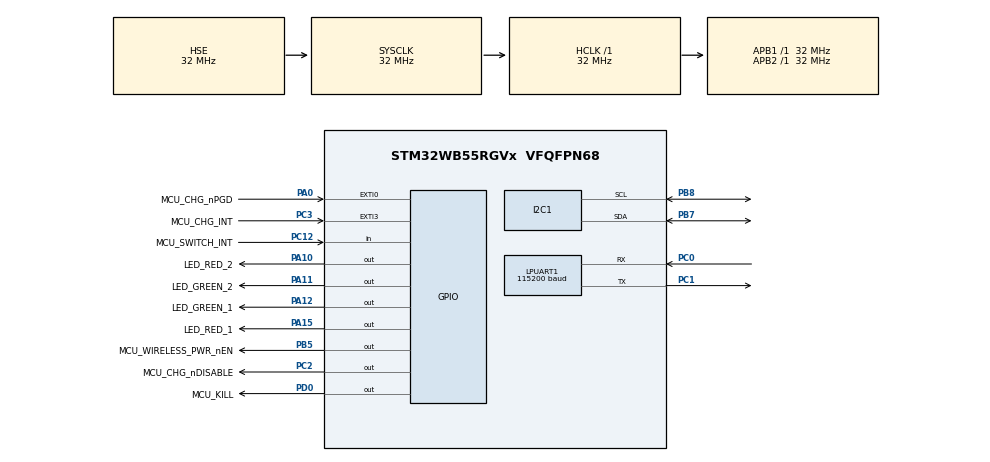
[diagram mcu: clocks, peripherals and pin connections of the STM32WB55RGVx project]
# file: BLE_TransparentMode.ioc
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Dma.LPUART1_TX.0.Direction=DMA_MEMORY_TO_PERIPH
Dma.LPUART1_TX.0.EventEnable=DISABLE
Dma.LPUART1_TX.0.Instance=DMA1_Channel2
Dma.LPUART1_TX.0.MemDataAlignment=DMA_MDATAALIGN_BYTE
Dma.LPUART1_TX.0.MemInc=DMA_MINC_ENABLE
Dma.LPUART1_TX.0.Mode=DMA_NORMAL
Dma.LPUART1_TX.0.PeriphDataAlignment=DMA_PDATAALIGN_BYTE
Dma.LPUART1_TX.0.PeriphInc=DMA_PINC_DISABLE
Dma.LPUART1_TX.0.Polarity=HAL_DMAMUX_REQ_GEN_RISING
Dma.LPUART1_TX.0.Priority=DMA_PRIORITY_LOW
Dma.LPUART1_TX.0.RequestNumber=1
Dma.LPUART1_TX.0.SignalID=NONE
Dma.LPUART1_TX.0.SyncEnable=DISABLE
Dma.LPUART1_TX.0.SyncPolarity=HAL_DMAMUX_SYNC_NO_EVENT
Dma.LPUART1_TX.0.SyncRequestNumber=1
Dma.LPUART1_TX.0.SyncSignalID=NONE
Dma.Request0=LPUART1_TX
I2C1.Timing=0x00B07CB4
LPUART1.BaudRate=115200
Mcu.Family=STM32WB
Mcu.Name=STM32WB55RGVx
Mcu.Package=VFQFPN68
NVIC.DMA1_Channel2_IRQn=true\:0\:0\:false\:false\:true\:false\:true\:true
NVIC.HSEM_IRQn=true\:0\:0\:false\:false\:true\:false\:true\:true
NVIC.IPCC_C1_RX_IRQn=true\:0\:0\:false\:false\:true\:true\:true\:true
NVIC.IPCC_C1_TX_IRQn=true\:0\:0\:false\:false\:true\:true\:true\:true
NVIC.LPUART1_IRQn=true\:0\:0\:false\:false\:true\:true\:true\:true
NVIC.PriorityGroup=NVIC_PRIORITYGROUP_4
NVIC.RTC_WKUP_IRQn=true\:0\:0\:false\:false\:true\:true\:true\:true
NVIC.TIM1_TRG_COM_TIM17_IRQn=true\:0\:0\:false\:false\:true\:true\:true\:true
OSC_IN.Mode=HSE-External-Oscillator
OSC_IN.Signal=RCC_OSC_IN
OSC_OUT.Mode=HSE-External-Oscillator
OSC_OUT.Signal=RCC_OSC_OUT
PA0.GPIO_Label=MCU_CHG_nPGD
PA0.Signal=GPXTI0
PA10.GPIO_Label=LED_RED_2
PA10.PinState=GPIO_PIN_SET
PA10.Signal=GPIO_Output
PA11.GPIO_Label=LED_GREEN_2
PA11.PinState=GPIO_PIN_SET
PA11.Signal=GPIO_Output
PA12.GPIO_Label=LED_GREEN_1
PA12.PinState=GPIO_PIN_SET
PA12.Signal=GPIO_Output
PA15.GPIO_Label=LED_RED_1
PA15.PinState=GPIO_PIN_SET
PA15.Signal=GPIO_Output
PB5.GPIO_Label=MCU_WIRELESS_PWR_nEN
PB5.Signal=GPIO_Output
PB7.Mode=I2C
PB7.Signal=I2C1_SDA
PB8.Mode=I2C
PB8.Signal=I2C1_SCL
PC0.Mode=Asynchronous
PC0.Signal=LPUART1_RX
PC1.Mode=Asynchronous
PC1.Signal=LPUART1_TX
PC12.GPIO_Label=MCU_SWITCH_INT
PC12.Signal=GPIO_Input
PC14-OSC32_IN.Mode=LSE-External-Oscillator
PC14-OSC32_IN.Signal=RCC_OSC32_IN
PC15-OSC32_OUT.Mode=LSE-External-Oscillator
PC15-OSC32_OUT.Signal=RCC_OSC32_OUT
PC2.GPIO_Label=MCU_CHG_nDISABLE
PC2.PinState=GPIO_PIN_SET
PC2.Signal=GPIO_Output
PC3.GPIO_Label=MCU_CHG_INT
PC3.Signal=GPXTI3
PD0.GPIO_Label=MCU_KILL
PD0.Signal=GPIO_Output
ProjectManager.HeapSize=0x400
ProjectManager.StackSize=0x1000
ProjectManager.TargetToolchain=EWARM V8
RCC.ADCFreq_Value=64000000
RCC.AHBFreq_Value=32000000
RCC.APB1Freq_Value=32000000
RCC.APB1TimFreq_Value=32000000
RCC.APB2Freq_Value=32000000
RCC.APB2TimFreq_Value=32000000
RCC.APB3Freq_Value=16000000
RCC.CortexFreq_Value=32000000
RCC.HCLKFreq_Value=32000000
RCC.HSE_VALUE=32000000
RCC.HSI48_VALUE=48000000
RCC.HSI_VALUE=16000000
RCC.LSE_Drive_Capability=RCC_LSEDRIVE_LOW
RCC.PLLSourceVirtual=RCC_PLLSOURCE_HSI
RCC.RFWKPClockSelection=RCC_RFWKPCLKSOURCE_LSE
RCC.RTCClockSelection=RCC_RTCCLKSOURCE_LSE
RCC.SMPSCLockSelection=RCC_SMPSCLKSOURCE_HSE
RCC.SMPSCLockSelectionVirtual=RCC_SMPSCLKSOURCE_HSE
RCC.SMPSDivider=4
RCC.SYSCLKFreq_VALUE=32000000
RCC.SYSCLKSource=RCC_SYSCLKSOURCE_HSE
RCC.USBFreq_Value=64000000
RCC.VCOOutputFreq_Value=128000000
RF1.Mode=RF1_Activate
RF1.Signal=RF_RF1
STM32_WPAN.BLE_APPLICATION_TYPE=TRANSPARENT_MODE
STM32_WPAN.CFG_BLE_LSE_SOURCE=0
STM32_WPAN.CFG_BLE_MAX_ADV_DATA_LEN=207
STM32_WPAN.CFG_BLE_MAX_ADV_SET_NBR=8
STM32_WPAN.CFG_BLE_MAX_CONN_EVENT_LENGTH=0xFFFFFFFF
STM32_WPAN.CFG_BLE_MAX_TX_POWER=6
STM32_WPAN.CFG_BLE_MIN_TX_POWER=-40
STM32_WPAN.CFG_BLE_NUM_LINK=8
STM32_WPAN.CFG_BLE_OPTIONS_CS_ALGO=SHCI_C2_BLE_INIT_OPTIONS_CS_ALGO2
STM32_WPAN.CFG_BLE_OPTIONS_EXT_ADV=SHCI_C2_BLE_INIT_OPTIONS_EXT_ADV
STM32_WPAN.CFG_DEBUGGER_SUPPORTED=1
STM32_WPAN.CFG_HW_LPUART1_ENABLED=1
STM32_WPAN.CFG_HW_USART1_ENABLED=1
STM32_WPAN.CFG_LPM_SUPPORTED=0
STM32_WPAN.CFG_RTCCLK_DIV=16
STM32_WPAN.CFG_RTCCLK_DIVIDER_CONF=0
STM32_WPAN.CFG_RTC_ASYNCH_PRESCALER=0x0F
STM32_WPAN.CFG_UART_GUI=hw_lpuart1
STM32_WPAN.CFG_USE_SMPS=0
TIM17.AutoReloadPreload=TIM_AUTORELOAD_PRELOAD_ENABLE
TIM17.Period=500
TIM17.Prescaler=31999
VP_HSEM_VS_HSEM.Mode=HSEM_Activate
VP_IPCC_VS_IPCC.Mode=IPCC_Activate
VP_MEMORYMAP_VS_MEMORYMAP.Mode=CurAppReg
VP_RTC_VS_RTC_Activate.Mode=RTC_Enabled
VP_RTC_VS_RTC_WakeUp_intern.Mode=WakeUp
VP_SEQUENCER_VS_SEQUENCER.Mode=SEQUENCER_Enabled
VP_STM32_WPAN_VS_BLE_HOST.Mode=STM32_WPAN_Enabled
VP_TIM17_VS_ClockSourceINT.Mode=Enable_Timer
VP_TINY_LPM_VS_TINY_LPM.Mode=TINY_LPM_Enabled
board=custom

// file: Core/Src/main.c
/* USER CODE BEGIN Header */
/**
  ******************************************************************************
 * @file    main.c
 * @author  MCD Application Team
 * @brief   BLE application with BLE core
 *
  ******************************************************************************
  * @attention
  *
  * Copyright (c) 2019-2021 STMicroelectronics.
  * All rights reserved.
  *
  * This software is licensed under terms that can be found in the LICENSE file
  * in the root directory of this software component.
  * If no LICENSE file comes with this software, it is provided AS-IS.
  *
  ******************************************************************************
  @verbatim
  ==============================================================================
                    ##### IMPORTANT NOTE #####
  ==============================================================================

  This application requests having the stm32wb5x_BLE_Stack_fw.bin binary
  flashed on the Wireless Coprocessor.
  If it is not the case, you need to use STM32CubeProgrammer to load the appropriate
  binary.

  All available binaries are located under following directory:
  /Projects/STM32_Copro_Wireless_Binaries

  Refer to UM2237 to learn how to use/install STM32CubeProgrammer.
  Refer to /Projects/STM32_Copro_Wireless_Binaries/ReleaseNote.html for the
  detailed procedure to change the Wireless Coprocessor binary.

  @endverbatim
  ******************************************************************************
  */
/* USER CODE END Header */
#include "main.h"

/* USER CODE BEGIN Includes */
#include "led.h"
#include "charger_control.h"

/* USER CODE END Includes */

I2C_HandleTypeDef hi2c1;

IPCC_HandleTypeDef hipcc;

UART_HandleTypeDef hlpuart1;
DMA_HandleTypeDef hdma_lpuart1_tx;

RTC_HandleTypeDef hrtc;

TIM_HandleTypeDef htim17;

void SystemClock_Config(void);
void PeriphCommonClock_Config(void);
static void MX_RF_Init(void);
static void MX_GPIO_Init(void);
static void MX_DMA_Init(void);
static void MX_RTC_Init(void);
static void MX_IPCC_Init(void);
void MX_LPUART1_UART_Init(void);
static void MX_I2C1_Init(void);
static void MX_TIM17_Init(void);

int main(void)
{

  /* MCU Configuration--------------------------------------------------------*/

  /* Reset of all peripherals, Initializes the Flash interface and the Systick. */
  HAL_Init();
  /* Config code for STM32_WPAN (HSE Tuning must be done before system clock configuration) */
  MX_APPE_Config();

  /* Configure the system clock */
  SystemClock_Config();

  /* Configure the peripherals common clocks */
  PeriphCommonClock_Config();

  /* IPCC initialisation */
  MX_IPCC_Init();

  /* Initialize all configured peripherals */
  MX_RF_Init();
  MX_GPIO_Init();
  MX_DMA_Init();
  MX_RTC_Init();
  MX_LPUART1_UART_Init();
  MX_I2C1_Init();
  MX_TIM17_Init();
  /* USER CODE BEGIN 2 */

  LED_Init();
  CHGC_Init();

  // only start the timer after LED & CHRG are initialised
  HAL_TIM_Base_Start_IT(&htim17);

  /* USER CODE END 2 */

  /* Init code for STM32_WPAN */
  MX_APPE_Init();

  /* Infinite loop */
	while(1)
	{
    MX_APPE_Process();

  }
}

void SystemClock_Config(void)
{
  RCC_OscInitTypeDef RCC_OscInitStruct = {0};
  RCC_ClkInitTypeDef RCC_ClkInitStruct = {0};

  /** Configure LSE Drive Capability
  */
  HAL_PWR_EnableBkUpAccess();
  __HAL_RCC_LSEDRIVE_CONFIG(RCC_LSEDRIVE_LOW);

  /** Configure the main internal regulator output voltage
  */
  __HAL_PWR_VOLTAGESCALING_CONFIG(PWR_REGULATOR_VOLTAGE_SCALE1);

  /** Initializes the RCC Oscillators according to the specified parameters
  * in the RCC_OscInitTypeDef structure.
  */
  RCC_OscInitStruct.OscillatorType = RCC_OSCILLATORTYPE_HSI|RCC_OSCILLATORTYPE_HSE
                              |RCC_OSCILLATORTYPE_LSE;
  RCC_OscInitStruct.HSEState = RCC_HSE_ON;
  RCC_OscInitStruct.LSEState = RCC_LSE_ON;
  RCC_OscInitStruct.HSIState = RCC_HSI_ON;
  RCC_OscInitStruct.HSICalibrationValue = RCC_HSICALIBRATION_DEFAULT;
  RCC_OscInitStruct.PLL.PLLState = RCC_PLL_NONE;
  if (HAL_RCC_OscConfig(&RCC_OscInitStruct) != HAL_OK)
  {
    Error_Handler();
  }

  /** Configure the SYSCLKSource, HCLK, PCLK1 and PCLK2 clocks dividers
  */
  RCC_ClkInitStruct.ClockType = RCC_CLOCKTYPE_HCLK4|RCC_CLOCKTYPE_HCLK2
                              |RCC_CLOCKTYPE_HCLK|RCC_CLOCKTYPE_SYSCLK
                              |RCC_CLOCKTYPE_PCLK1|RCC_CLOCKTYPE_PCLK2;
  RCC_ClkInitStruct.SYSCLKSource = RCC_SYSCLKSOURCE_HSE;
  RCC_ClkInitStruct.AHBCLKDivider = RCC_SYSCLK_DIV1;
  RCC_ClkInitStruct.APB1CLKDivider = RCC_HCLK_DIV1;
  RCC_ClkInitStruct.APB2CLKDivider = RCC_HCLK_DIV1;
  RCC_ClkInitStruct.AHBCLK2Divider = RCC_SYSCLK_DIV1;
  RCC_ClkInitStruct.AHBCLK4Divider = RCC_SYSCLK_DIV1;

  if (HAL_RCC_ClockConfig(&RCC_ClkInitStruct, FLASH_LATENCY_1) != HAL_OK)
  {
    Error_Handler();
  }
}

void PeriphCommonClock_Config(void)
{
  RCC_PeriphCLKInitTypeDef PeriphClkInitStruct = {0};

  /** Initializes the peripherals clock
  */
  PeriphClkInitStruct.PeriphClockSelection = RCC_PERIPHCLK_SMPS|RCC_PERIPHCLK_RFWAKEUP;
  PeriphClkInitStruct.RFWakeUpClockSelection = RCC_RFWKPCLKSOURCE_LSE;
  PeriphClkInitStruct.SmpsClockSelection = RCC_SMPSCLKSOURCE_HSE;
  PeriphClkInitStruct.SmpsDivSelection = RCC_SMPSCLKDIV_RANGE1;

  if (HAL_RCCEx_PeriphCLKConfig(&PeriphClkInitStruct) != HAL_OK)
  {
    Error_Handler();
  }
}

static void MX_I2C1_Init(void)
{

  hi2c1.Instance = I2C1;
  hi2c1.Init.Timing = 0x00B07CB4;
  hi2c1.Init.OwnAddress1 = 0;
  hi2c1.Init.AddressingMode = I2C_ADDRESSINGMODE_7BIT;
  hi2c1.Init.DualAddressMode = I2C_DUALADDRESS_DISABLE;
  hi2c1.Init.OwnAddress2 = 0;
  hi2c1.Init.OwnAddress2Masks = I2C_OA2_NOMASK;
  hi2c1.Init.GeneralCallMode = I2C_GENERALCALL_DISABLE;
  hi2c1.Init.NoStretchMode = I2C_NOSTRETCH_DISABLE;
  if (HAL_I2C_Init(&hi2c1) != HAL_OK)
  {
    Error_Handler();
  }

  /** Configure Analogue filter
  */
  if (HAL_I2CEx_ConfigAnalogFilter(&hi2c1, I2C_ANALOGFILTER_ENABLE) != HAL_OK)
  {
    Error_Handler();
  }

  /** Configure Digital filter
  */
  if (HAL_I2CEx_ConfigDigitalFilter(&hi2c1, 0) != HAL_OK)
  {
    Error_Handler();
  }

}

static void MX_IPCC_Init(void)
{

  hipcc.Instance = IPCC;
  if (HAL_IPCC_Init(&hipcc) != HAL_OK)
  {
    Error_Handler();
  }

}

void MX_LPUART1_UART_Init(void)
{

  hlpuart1.Instance = LPUART1;
  hlpuart1.Init.BaudRate = 115200;
  hlpuart1.Init.WordLength = UART_WORDLENGTH_8B;
  hlpuart1.Init.StopBits = UART_STOPBITS_1;
  hlpuart1.Init.Parity = UART_PARITY_NONE;
  hlpuart1.Init.Mode = UART_MODE_TX_RX;
  hlpuart1.Init.HwFlowCtl = UART_HWCONTROL_NONE;
  hlpuart1.Init.OneBitSampling = UART_ONE_BIT_SAMPLE_DISABLE;
  hlpuart1.Init.ClockPrescaler = UART_PRESCALER_DIV1;
  hlpuart1.AdvancedInit.AdvFeatureInit = UART_ADVFEATURE_NO_INIT;
  hlpuart1.FifoMode = UART_FIFOMODE_DISABLE;
  if (HAL_UART_Init(&hlpuart1) != HAL_OK)
  {
    Error_Handler();
  }
  if (HAL_UARTEx_SetTxFifoThreshold(&hlpuart1, UART_TXFIFO_THRESHOLD_1_8) != HAL_OK)
  {
    Error_Handler();
  }
  if (HAL_UARTEx_SetRxFifoThreshold(&hlpuart1, UART_RXFIFO_THRESHOLD_1_8) != HAL_OK)
  {
    Error_Handler();
  }
  if (HAL_UARTEx_DisableFifoMode(&hlpuart1) != HAL_OK)
  {
    Error_Handler();
  }

}

static void MX_RF_Init(void)
{

}

static void MX_RTC_Init(void)
{

  /** Initialize RTC Only
  */
  hrtc.Instance = RTC;
  hrtc.Init.HourFormat = RTC_HOURFORMAT_24;
  hrtc.Init.AsynchPrediv = CFG_RTC_ASYNCH_PRESCALER;
  hrtc.Init.SynchPrediv = CFG_RTC_SYNCH_PRESCALER;
  hrtc.Init.OutPut = RTC_OUTPUT_DISABLE;
  hrtc.Init.OutPutPolarity = RTC_OUTPUT_POLARITY_HIGH;
  hrtc.Init.OutPutType = RTC_OUTPUT_TYPE_OPENDRAIN;
  hrtc.Init.OutPutRemap = RTC_OUTPUT_REMAP_NONE;
  if (HAL_RTC_Init(&hrtc) != HAL_OK)
  {
    Error_Handler();
  }

  /** Enable the WakeUp
  */
  if (HAL_RTCEx_SetWakeUpTimer_IT(&hrtc, 0, RTC_WAKEUPCLOCK_RTCCLK_DIV16) != HAL_OK)
  {
    Error_Handler();
  }

}

static void MX_TIM17_Init(void)
{

  htim17.Instance = TIM17;
  htim17.Init.Prescaler = 31999;
  htim17.Init.CounterMode = TIM_COUNTERMODE_UP;
  htim17.Init.Period = 500;
  htim17.Init.ClockDivision = TIM_CLOCKDIVISION_DIV1;
  htim17.Init.RepetitionCounter = 0;
  htim17.Init.AutoReloadPreload = TIM_AUTORELOAD_PRELOAD_ENABLE;
  if (HAL_TIM_Base_Init(&htim17) != HAL_OK)
  {
    Error_Handler();
  }

}

static void MX_DMA_Init(void)
{

  /* DMA controller clock enable */
  __HAL_RCC_DMAMUX1_CLK_ENABLE();
  __HAL_RCC_DMA1_CLK_ENABLE();

  /* DMA interrupt init */
  /* DMA1_Channel2_IRQn interrupt configuration */
  HAL_NVIC_SetPriority(DMA1_Channel2_IRQn, 0, 0);
  HAL_NVIC_EnableIRQ(DMA1_Channel2_IRQn);

}

static void MX_GPIO_Init(void)
{
  GPIO_InitTypeDef GPIO_InitStruct = {0};

  /* GPIO Ports Clock Enable */
  __HAL_RCC_GPIOC_CLK_ENABLE();
  __HAL_RCC_GPIOB_CLK_ENABLE();
  __HAL_RCC_GPIOA_CLK_ENABLE();
  __HAL_RCC_GPIOD_CLK_ENABLE();

  /*Configure GPIO pin Output Level */
  HAL_GPIO_WritePin(MCU_CHG_nDISABLE_GPIO_Port, MCU_CHG_nDISABLE_Pin, GPIO_PIN_SET);

  /*Configure GPIO pin Output Level */
  HAL_GPIO_WritePin(GPIOA, LED_RED_2_Pin|LED_GREEN_2_Pin|LED_GREEN_1_Pin|LED_RED_1_Pin, GPIO_PIN_SET);

  /*Configure GPIO pin Output Level */
  HAL_GPIO_WritePin(MCU_KILL_GPIO_Port, MCU_KILL_Pin, GPIO_PIN_RESET);

  /*Configure GPIO pin Output Level */
  HAL_GPIO_WritePin(MCU_WIRELESS_PWR_nEN_GPIO_Port, MCU_WIRELESS_PWR_nEN_Pin, GPIO_PIN_RESET);

  /*Configure GPIO pin : MCU_CHG_nDISABLE_Pin */
  GPIO_InitStruct.Pin = MCU_CHG_nDISABLE_Pin;
  GPIO_InitStruct.Mode = GPIO_MODE_OUTPUT_PP;
  GPIO_InitStruct.Pull = GPIO_NOPULL;
  GPIO_InitStruct.Speed = GPIO_SPEED_FREQ_LOW;
  HAL_GPIO_Init(MCU_CHG_nDISABLE_GPIO_Port, &GPIO_InitStruct);

  /*Configure GPIO pin : MCU_CHG_INT_Pin */
  GPIO_InitStruct.Pin = MCU_CHG_INT_Pin;
  GPIO_InitStruct.Mode = GPIO_MODE_IT_RISING;
  GPIO_InitStruct.Pull = GPIO_NOPULL;
  HAL_GPIO_Init(MCU_CHG_INT_GPIO_Port, &GPIO_InitStruct);

  /*Configure GPIO pin : MCU_CHG_nPGD_Pin */
  GPIO_InitStruct.Pin = MCU_CHG_nPGD_Pin;
  GPIO_InitStruct.Mode = GPIO_MODE_IT_RISING;
  GPIO_InitStruct.Pull = GPIO_NOPULL;
  HAL_GPIO_Init(MCU_CHG_nPGD_GPIO_Port, &GPIO_InitStruct);

  /*Configure GPIO pins : LED_RED_2_Pin LED_GREEN_2_Pin LED_GREEN_1_Pin LED_RED_1_Pin */
  GPIO_InitStruct.Pin = LED_RED_2_Pin|LED_GREEN_2_Pin|LED_GREEN_1_Pin|LED_RED_1_Pin;
  GPIO_InitStruct.Mode = GPIO_MODE_OUTPUT_PP;
  GPIO_InitStruct.Pull = GPIO_NOPULL;
  GPIO_InitStruct.Speed = GPIO_SPEED_FREQ_LOW;
  HAL_GPIO_Init(GPIOA, &GPIO_InitStruct);

  /*Configure GPIO pin : MCU_SWITCH_INT_Pin */
  GPIO_InitStruct.Pin = MCU_SWITCH_INT_Pin;
  GPIO_InitStruct.Mode = GPIO_MODE_INPUT;
  GPIO_InitStruct.Pull = GPIO_NOPULL;
  HAL_GPIO_Init(MCU_SWITCH_INT_GPIO_Port, &GPIO_InitStruct);

  /*Configure GPIO pin : MCU_KILL_Pin */
  GPIO_InitStruct.Pin = MCU_KILL_Pin;
  GPIO_InitStruct.Mode = GPIO_MODE_OUTPUT_PP;
  GPIO_InitStruct.Pull = GPIO_NOPULL;
  GPIO_InitStruct.Speed = GPIO_SPEED_FREQ_LOW;
  HAL_GPIO_Init(MCU_KILL_GPIO_Port, &GPIO_InitStruct);

  /*Configure GPIO pin : MCU_WIRELESS_PWR_nEN_Pin */
  GPIO_InitStruct.Pin = MCU_WIRELESS_PWR_nEN_Pin;
  GPIO_InitStruct.Mode = GPIO_MODE_OUTPUT_PP;
  GPIO_InitStruct.Pull = GPIO_NOPULL;
  GPIO_InitStruct.Speed = GPIO_SPEED_FREQ_LOW;
  HAL_GPIO_Init(MCU_WIRELESS_PWR_nEN_GPIO_Port, &GPIO_InitStruct);

}

/* USER CODE BEGIN 4 */

void HAL_TIM_PeriodElapsedCallback(TIM_HandleTypeDef *htim)
{
  if (htim == (&htim17))
  {
    LED_Process();
    CHGC_ChargerStatusMonitoringThread();
  }
}

/* USER CODE END 4 */

void Error_Handler(void)
{
}
